# FM33FG0XXA register map
File version: 1.0
CPU: SC000 r1p0, little endian, MPU, no FPU, 3 interrupt priority bits
Registers are 32-bit, read-only, reset 0x0 unless marked. A register's access mark holds for its fields unless they carry their own. Offsets are from the block's base; [hi:lo] are bit positions; {n}, {i} and the like mark numbered series.

## AES — AES module information
Base 0x40013800
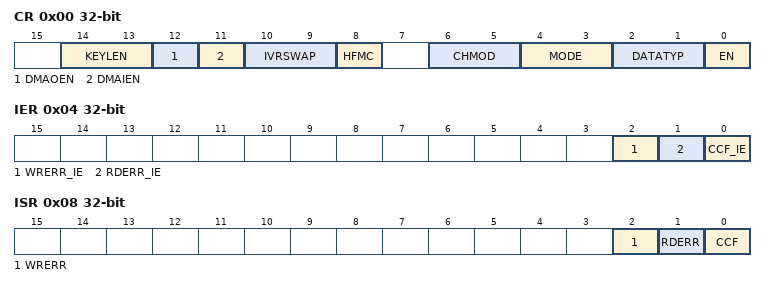
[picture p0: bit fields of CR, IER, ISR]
0x00 CR rw — AES Control Register
  [14:13] KEYLEN — KEYLEN field description
  [12] DMAOEN — DMAOEN field description
  [11] DMAIEN — DMAIEN field description
  [10:9] IVRSWAP — IVRSWAP field description
  [8] HFMC — HFMC field description
  [6:5] CHMOD — CHMOD field description
  [4:3] MODE — MODE field description
  [2:1] DATATYP — DATATYP field description
  [0] EN — EN field description
0x04 IER rw — AES Interrupt Enable Register
  [2] WRERR_IE — WRERR_IE field description
  [1] RDERR_IE — RDERR_IE field description
  [0] CCF_IE — CCF_IE field description
0x08 ISR rw — AES Interrupt Status Register
  [2] WRERR — WRERR field description
  [1] RDERR — RDERR field description
  [0] CCF — CCF field description
0x0C DIR rw — AES Data Input Register
  [31:0] DIN — DIN field description
0x10 DOR — AES Data Output Register
  [31:0] DOUT — DOUT field description
{0x14+4i} KEY{i} rw (i=0..7) — AES Key Register {i}
  [31:0] KEYx — KEYx field description
{0x34+4i} IVR{i} rw (i=0..3) — AES Initial Vector Register {i}
  [31:0] IVRx — IVRx field description
{0x44+4i} H{i} rw (i=0..3) — AES MultH parameter Register {i}
  [31:0] Hx — Hx field description

## RNG — RNG module information
Base 0x40013C00
0x00 CR rw — Rand Number Generator Control Register
  [0] RNGEN — RNGEN field description
0x04 DOR — Rand Number/DRD Generator Control Data Output Register
  [31:0] RNGOUT — RNGOUT field description
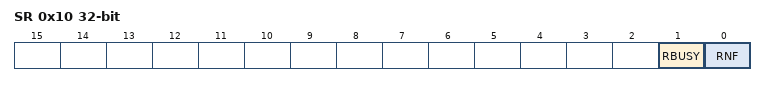
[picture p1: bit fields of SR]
0x10 SR access per field — Rand Number Generator Status Register
  [1] RBUSY ro — RBUSY field description
  [0] RNF rw — RNF field description
0x14 CRCCR rw — CRC Data Input Register
  [0] CRCEN — CRCEN field description
0x18 CRCDIR rw — CRC Control Register
  [31:0] CRCIN — CRCIN field description
0x1C CRCSR rw — CRC Status Register
  [0] CRCDONE — CRCDONE field description

## COMP — COMP module information
Base 0x40015400
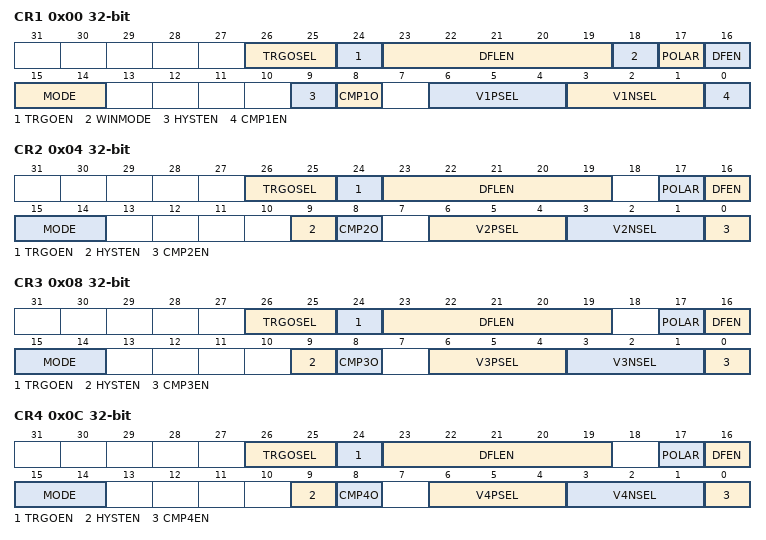
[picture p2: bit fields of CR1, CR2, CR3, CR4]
0x00 CR1 access per field
  [26:25] TRGOSEL rw — TRGOSEL field description
  [24] TRGOEN rw — TRGOEN field description
  [23:19] DFLEN rw — DFLEN field description
  [18] WINMODE rw — WINMODE field description
  [17] POLAR rw — POLAR field description
  [16] DFEN rw — DFEN field description
  [15:14] MODE rw — MODE field description
  [9] HYSTEN rw — HYSTEN field description
  [8] CMP1O ro — CMP1O field description
  [6:4] V1PSEL rw — V1PSEL field description
  [3:1] V1NSEL rw — V1NSEL field description
  [0] CMP1EN rw — CMP1EN field description
0x04 CR2 access per field
  [26:25] TRGOSEL rw — TRGOSEL field description
  [24] TRGOEN rw — TRGOEN field description
  [23:19] DFLEN rw — DFLEN field description
  [17] POLAR rw — POLAR field description
  [16] DFEN rw — DFEN field description
  [15:14] MODE rw — MODE field description
  [9] HYSTEN rw — HYSTEN field description
  [8] CMP2O ro — CMP2O field description
  [6:4] V2PSEL rw — V2PSEL field description
  [3:1] V2NSEL rw — V2NSEL field description
  [0] CMP2EN rw — CMP2EN field description
0x08 CR3 access per field
  [26:25] TRGOSEL rw — TRGOSEL field description
  [24] TRGOEN rw — TRGOEN field description
  [23:19] DFLEN rw — DFLEN field description
  [17] POLAR rw — POLAR field description
  [16] DFEN rw — DFEN field description
  [15:14] MODE rw — MODE field description
  [9] HYSTEN rw — HYSTEN field description
  [8] CMP3O ro — CMP3O field description
  [6:4] V3PSEL rw — V3PSEL field description
  [3:1] V3NSEL rw — V3NSEL field description
  [0] CMP3EN rw — CMP3EN field description
0x0C CR4 access per field
  [26:25] TRGOSEL rw — TRGOSEL field description
  [24] TRGOEN rw — TRGOEN field description
  [23:19] DFLEN rw — DFLEN field description
  [17] POLAR rw — POLAR field description
  [16] DFEN rw — DFEN field description
  [15:14] MODE rw — MODE field description
  [9] HYSTEN rw — HYSTEN field description
  [8] CMP4O ro — CMP4O field description
  [6:4] V4PSEL rw — V4PSEL field description
  [3:1] V4NSEL rw — V4NSEL field description
  [0] CMP4EN rw — CMP4EN field description
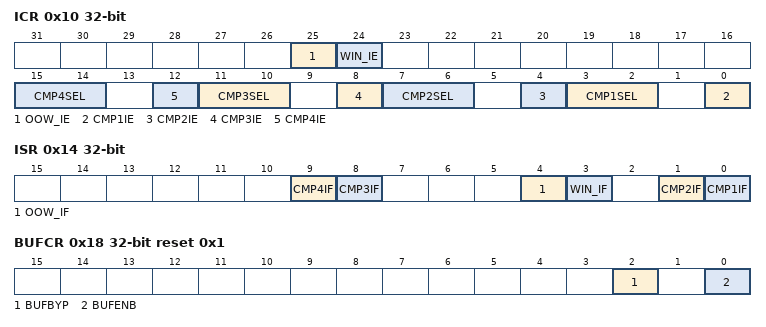
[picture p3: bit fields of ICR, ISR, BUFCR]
0x10 ICR rw
  [25] OOW_IE — OOW_IE field description
  [24] WIN_IE — WIN_IE field description
  [4n-1:4n-2] CMP{n}SEL (n=1..4) — CMP{n}SEL field description
  [4n-4] CMP{n}IE (n=1..4) — CMP{n}IE field description
0x14 ISR rw
  [9] CMP4IF — CMP4IF field description
  [8] CMP3IF — CMP3IF field description
  [4] OOW_IF — OOW_IF field description
  [3] WIN_IF — WIN_IF field description
  [1] CMP2IF — CMP2IF field description
  [0] CMP1IF — CMP1IF field description
0x18 BUFCR rw reset 0x1
  [2] BUFBYP — BUFBYP field description
  [0] BUFENB — BUFENB field description
